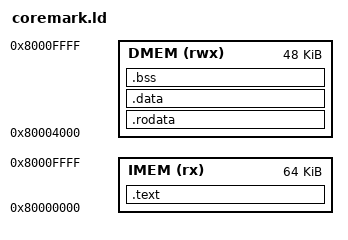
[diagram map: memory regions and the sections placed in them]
ENTRY(_start)

MEMORY
{
    IMEM (rx)  : ORIGIN = 0x80000000, LENGTH = 0x10000
    DMEM (rwx) : ORIGIN = 0x80004000, LENGTH = 0xC000
}

SECTIONS
{
    .text : {
        *(.text)
        *(.text.*)
    } > IMEM

    .rodata : {
        *(.rodata)
        *(.rodata.*)
        *(.srodata)
        *(.srodata.*)
    } > DMEM

    .data : {
        *(.data)
        *(.data.*)
        *(.sdata)
        *(.sdata.*)
    } > DMEM

    .bss : {
        _bss_start = .;
        *(.bss)
        *(.bss.*)
        *(.sbss)
        *(.sbss.*)
        *(COMMON)
        _bss_end = .;
    } > DMEM
}
